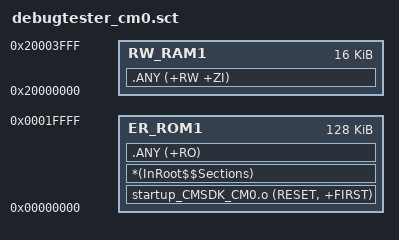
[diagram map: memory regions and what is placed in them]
; ----------------------------------------------------------------
; The confidential and proprietary information contained in this file may
; only be used by a person authorised under and to the extent permitted
; by a subsisting licensing agreement from ARM Limited or its affiliates.
;
;            (C) COPYRIGHT 2010-2013 ARM Limited or its affiliates.
;                ALL RIGHTS RESERVED
;
; This entire notice must be reproduced on all copies of this file
; and copies of this file may only be made by a person if such person is
; permitted to do so under the terms of a subsisting license agreement
; from ARM Limited or its affiliates.
;
;  Version and Release Control Information:
;
;  File Revision       : $Revision: 368444 $
;  File Date           : $Date: 2017-07-25 15:10:13 +0100 (Tue, 25 Jul 2017) $
;
;  Release Information : Cortex-M0 DesignStart-r2p0-00rel0
;
; ----------------------------------------------------------------

; *************************************************************
; *** Scatter-Loading Description File generated by uVision ***
; *************************************************************

LR_ROM1 0x00000000 0x00020000  {    ; load region size_region
  ER_ROM1 0x00000000 0x00020000  {  ; load address = execution address
   startup_CMSDK_CM0.o (RESET, +FIRST)
   *(InRoot$$Sections)
   .ANY (+RO)
  }
  RW_RAM1 0x20000000 0x00004000  {  ; RW data
   .ANY (+RW +ZI)
  }
}

